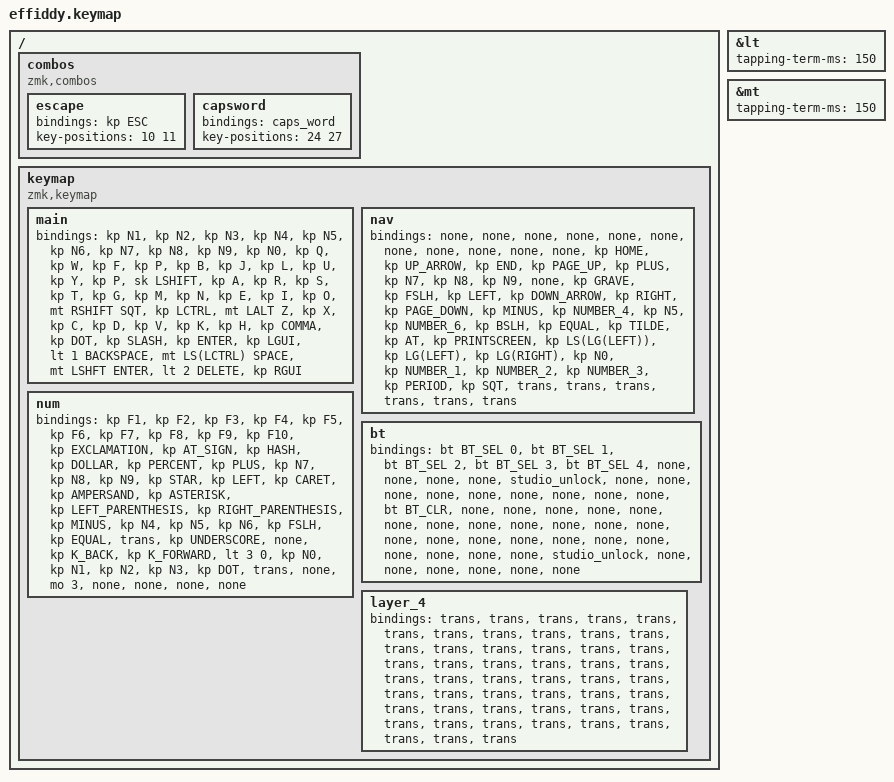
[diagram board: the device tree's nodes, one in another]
#include <behaviors.dtsi>
#include <dt-bindings/zmk/bt.h>
#include <dt-bindings/zmk/keys.h>

&lt { tapping-term-ms = <150>; };

&mt { tapping-term-ms = <150>; };

/ {
    combos {
        compatible = "zmk,combos";

        escape {
            bindings = <&kp ESC>;
            key-positions = <10 11>;
        };

        capsword {
            bindings = <&caps_word>;
            key-positions = <24 27>;
        };
    };

    keymap {
        compatible = "zmk,keymap";

        main {
            bindings = <
&kp N1  &kp N2  &kp N3  &kp N4  &kp N5  &kp N6  &kp N7  &kp N8  &kp N9  &kp N0  &kp Q  &kp W  &kp F  &kp P  &kp B  &kp J  &kp L  &kp U  &kp Y  &kp P  &sk LSHIFT  &kp A  &kp R  &kp S  &kp T  &kp G  &kp M  &kp N  &kp E  &kp I  &kp O  &mt RSHIFT SQT  &kp LCTRL  &mt LALT Z  &kp X  &kp C  &kp D  &kp V  &kp K  &kp H  &kp COMMA  &kp DOT  &kp SLASH  &kp ENTER  &kp LGUI  &lt 1 BACKSPACE  &mt LS(LCTRL) SPACE  &mt LSHFT ENTER  &lt 2 DELETE  &kp RGUI
            >;
        };

        nav {
            bindings = <
&none  &none  &none  &none  &none  &none  &none  &none  &none  &none  &none  &kp HOME  &kp UP_ARROW  &kp END  &kp PAGE_UP  &kp PLUS  &kp N7  &kp N8  &kp N9  &none  &kp GRAVE  &kp FSLH  &kp LEFT  &kp DOWN_ARROW  &kp RIGHT  &kp PAGE_DOWN  &kp MINUS  &kp NUMBER_4  &kp N5  &kp NUMBER_6  &kp BSLH  &kp EQUAL  &kp TILDE  &kp AT  &kp PRINTSCREEN  &kp LS(LG(LEFT))  &kp LG(LEFT)  &kp LG(RIGHT)  &kp N0  &kp NUMBER_1  &kp NUMBER_2  &kp NUMBER_3  &kp PERIOD  &kp SQT  &trans  &trans  &trans  &trans  &trans  &trans
            >;
        };

        num {
            bindings = <
&kp F1  &kp F2  &kp F3  &kp F4  &kp F5  &kp F6  &kp F7  &kp F8  &kp F9  &kp F10  &kp EXCLAMATION  &kp AT_SIGN  &kp HASH  &kp DOLLAR  &kp PERCENT  &kp PLUS  &kp N7  &kp N8  &kp N9  &kp STAR  &kp LEFT  &kp CARET  &kp AMPERSAND  &kp ASTERISK  &kp LEFT_PARENTHESIS  &kp RIGHT_PARENTHESIS  &kp MINUS  &kp N4  &kp N5  &kp N6  &kp FSLH  &kp EQUAL  &trans  &kp UNDERSCORE  &none  &kp K_BACK  &kp K_FORWARD  &lt 3 0  &kp N0  &kp N1  &kp N2  &kp N3  &kp DOT  &trans  &none  &mo 3  &none  &none  &none  &none
            >;
        };

        bt {
            bindings = <
&bt BT_SEL 0  &bt BT_SEL 1  &bt BT_SEL 2  &bt BT_SEL 3  &bt BT_SEL 4  &none  &none  &none  &none  &studio_unlock  &none  &none  &none  &none  &none  &none  &none  &none  &none  &bt BT_CLR  &none  &none  &none  &none  &none  &none  &none  &none  &none  &none  &none  &none  &none  &none  &none  &none  &none  &none  &none  &none  &none  &none  &none  &studio_unlock  &none  &none  &none  &none  &none  &none
            >;
        };

        layer_4 {
            bindings = <
&trans  &trans  &trans  &trans  &trans  &trans  &trans  &trans  &trans  &trans  &trans  &trans  &trans  &trans  &trans  &trans  &trans  &trans  &trans  &trans  &trans  &trans  &trans  &trans  &trans  &trans  &trans  &trans  &trans  &trans  &trans  &trans  &trans  &trans  &trans  &trans  &trans  &trans  &trans  &trans  &trans  &trans  &trans  &trans  &trans  &trans  &trans  &trans  &trans  &trans
            >;
        };
    };
};
